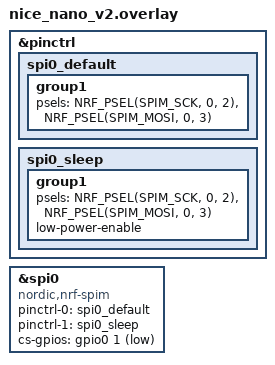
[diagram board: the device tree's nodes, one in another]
&pinctrl {
    /* configuration for spi0 device, default state */
    spi0_default: spi0_default {
        /* node name is arbitrary */
        group1 {
            /* main role: configure P0.01 as SPI clock, P0.02 as SPI MOSI */
            psels = <NRF_PSEL(SPIM_SCK, 0, 2)>,
                    <NRF_PSEL(SPIM_MOSI, 0, 3)>;
        };
    };

    /* configuration for spi0 device, sleep state */
    spi0_sleep: spi0_sleep {
        group1 {
            /* main role: configure P0.01 as SPI clock, P0.02 as SPI MOSI */
            psels = <NRF_PSEL(SPIM_SCK, 0, 2)>,
                    <NRF_PSEL(SPIM_MOSI, 0, 3)>;
            low-power-enable;
        };
    };

};

&spi0 {
    compatible = "nordic,nrf-spim";
	status = "okay";
    pinctrl-0 = <&spi0_default>;
    pinctrl-1 = <&spi0_sleep>;
    pinctrl-names = "default", "sleep";

    cs-gpios = <&gpio0 1 GPIO_ACTIVE_LOW>;
};
